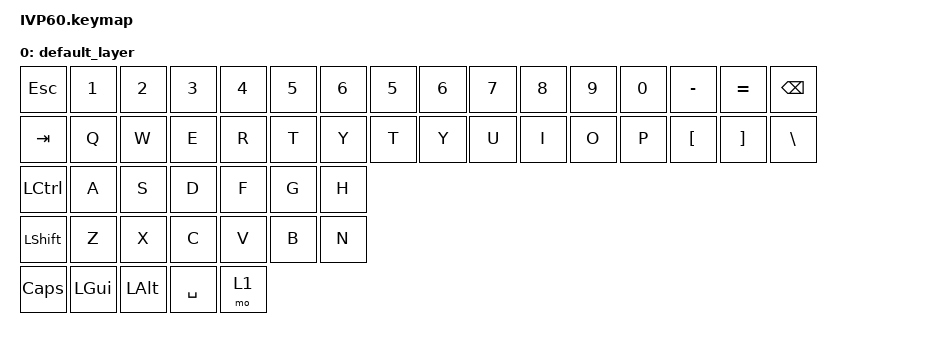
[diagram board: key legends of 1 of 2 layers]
#include <behaviors.dtsi>
#include <dt-bindings/zmk/keys.h>
#include <dt-bindings/zmk/bt.h>

/ {
	keymap {
		compatible = "zmk,keymap";
		
		default_layer {
			bindings = <
				&kp ESC   		&kp N1    		&kp N2    		&kp N3    		&kp N4    		&kp N5    		&kp N6    		     &kp N5		&kp N6		&kp N7		&kp N8		&kp N9		&kp N0		&kp MINUS		&kp EQUAL		&kp BSPC 
				&kp TAB   		&kp Q     		&kp W     		&kp E     		&kp R     		&kp T     		&kp Y     		     &kp T 		&kp Y 		&kp U 		&kp I 		&kp O 		&kp P 		&kp LBKT 		&kp RBKT 		&kp BSLH 
				&kp LCTRL 		&kp A     		&kp S     		&kp D     		&kp F     		&kp G     		&kp H     		
				&kp LSHFT 		&kp Z     		&kp X     		&kp C     		&kp V     		&kp B     		&kp N     		
				&kp CLCK  		&kp LGUI  		&kp LALT  		&kp SPACE 		&mo 1     		
			>;
		};
		
		bt_layer {
			bindings = <
				&none					&none					&bootloader				&kp Z		&kp Y		&kp W
				&none					&none					&bt BT_CLR				&kp H		&kp Q		&kp O
				&bt BT_SEL 0	&bt BT_SEL 1	&bt BT_SEL 2			&kp P		&kp Y		&kp W
			>;
		};
	};
};


